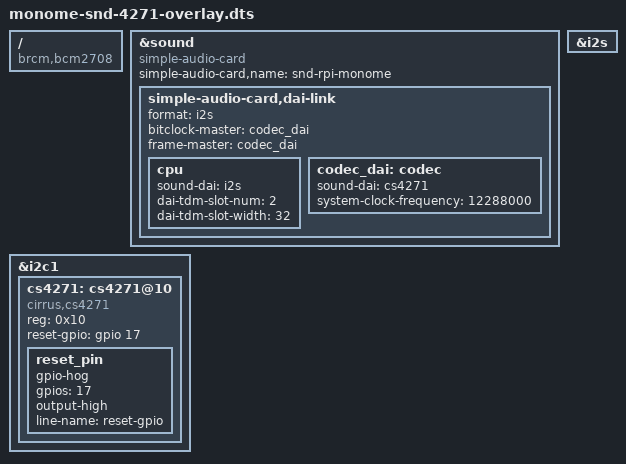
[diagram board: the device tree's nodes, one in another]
// Definitions for monome-snd
/dts-v1/;
/plugin/;

/ {
	compatible = "brcm,bcm2708";

	fragment@0 {
		target = <&sound>;
		__overlay__ {
			compatible = "simple-audio-card";
			status = "okay";
			simple-audio-card,name = "snd-rpi-monome";
			simple-audio-card,dai-link {
				format = "i2s";
				bitclock-master = <&codec_dai>;
				frame-master = <&codec_dai>;
				cpu {
					sound-dai = <&i2s>;
					dai-tdm-slot-num = <2>;
					dai-tdm-slot-width = <32>;
				};
				codec_dai: codec {
					sound-dai = <&cs4271>;
					system-clock-frequency = <12288000>;
				};
			};
		};
	};

	fragment@1 {
		target = <&i2s>;
		__overlay__ {
			status = "okay";
		};
	};

	fragment@2 {
		target = <&i2c1>;
		__overlay__ {
			#address-cells = <1>;
			#size-cells = <0>;
			status = "okay";

			cs4271: cs4271@10 {
				#sound-dai-cells = <0>;
				compatible = "cirrus,cs4271";
				reg = <0x10>;
				reset-gpio = <&gpio 17 2>;
				status = "okay";

				reset_pin {
				  gpio-hog;
				  gpios = <17>;
				  output-high;
				  line-name = "reset-gpio";
				};
            };
		};
	};
};
